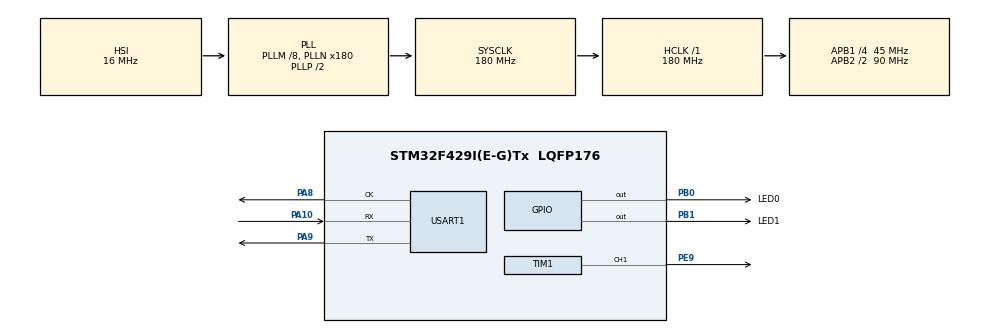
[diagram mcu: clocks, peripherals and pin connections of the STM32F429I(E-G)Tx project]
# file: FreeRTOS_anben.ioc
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FREERTOS.Tasks01=defaultTask,24,128,StartDefaultTask,Default,NULL,Dynamic,NULL,NULL
FREERTOS.configUSE_NEWLIB_REENTRANT=1
Mcu.Family=STM32F4
Mcu.Name=STM32F429I(E-G)Tx
Mcu.Package=LQFP176
NVIC.PriorityGroup=NVIC_PRIORITYGROUP_4
NVIC.TIM2_IRQn=true\:15\:0\:false\:false\:true\:false\:false\:true\:true
NVIC.TimeBase=TIM2_IRQn
NVIC.TimeBaseIP=TIM2
PA0/WKUP.Mode=SYS_WakeUp0
PA0/WKUP.Signal=SYS_WKUP
PA10.Mode=Synchronous
PA10.Signal=USART1_RX
PA13.Mode=Serial_Wire
PA13.Signal=SYS_JTMS-SWDIO
PA14.Mode=Serial_Wire
PA14.Signal=SYS_JTCK-SWCLK
PA8.Mode=Synchronous
PA8.Signal=USART1_CK
PA9.Mode=Synchronous
PA9.Signal=USART1_TX
PB0.GPIO_Label=LED0
PB0.Signal=GPIO_Output
PB1.GPIO_Label=LED1
PB1.Signal=GPIO_Output
PC14/OSC32_IN.Mode=LSE-External-Oscillator
PC14/OSC32_IN.Signal=RCC_OSC32_IN
PC15/OSC32_OUT.Mode=LSE-External-Oscillator
PC15/OSC32_OUT.Signal=RCC_OSC32_OUT
PE9.Signal=S_TIM1_CH1
PH0/OSC_IN.Mode=HSE-External-Oscillator
PH0/OSC_IN.Signal=RCC_OSC_IN
PH1/OSC_OUT.Mode=HSE-External-Oscillator
PH1/OSC_OUT.Signal=RCC_OSC_OUT
ProjectManager.HeapSize=0x200
ProjectManager.StackSize=0x400
ProjectManager.TargetToolchain=STM32CubeIDE
RCC.48MHZClocksFreq_Value=90000000
RCC.AHBFreq_Value=180000000
RCC.APB1CLKDivider=RCC_HCLK_DIV4
RCC.APB1Freq_Value=45000000
RCC.APB1TimFreq_Value=90000000
RCC.APB2CLKDivider=RCC_HCLK_DIV2
RCC.APB2Freq_Value=90000000
RCC.APB2TimFreq_Value=180000000
RCC.CortexFreq_Value=180000000
RCC.HCLKFreq_Value=180000000
RCC.HSE_VALUE=8000000
RCC.HSI_VALUE=16000000
RCC.PLLM=8
RCC.PLLN=180
RCC.SYSCLKFreq_VALUE=180000000
RCC.SYSCLKSource=RCC_SYSCLKSOURCE_PLLCLK
RCC.VCOOutputFreq_Value=360000000
SH.S_TIM1_CH1.0=TIM1_CH1,Output Compare1 CH1
TIM1.Channel-Output\ Compare1\ CH1=TIM_CHANNEL_1
USART1.VirtualMode=VM_SYNC
VP_FREERTOS_VS_CMSIS_V2.Mode=CMSIS_V2
VP_SYS_VS_tim2.Mode=TIM2
VP_TIM1_VS_ClockSourceINT.Mode=Internal
VP_TIM1_VS_ClockSourceITR.Mode=TriggerSource_ITR0
VP_TIM1_VS_ControllerModeReset.Mode=Reset Mode
board=custom

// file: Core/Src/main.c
/* USER CODE BEGIN Header */
/**
  ******************************************************************************
  * @file           : main.c
  * @brief          : Main program body
  ******************************************************************************
  * @attention
  *
  * Copyright (c) 2024 STMicroelectronics.
  * All rights reserved.
  *
  * This software is licensed under terms that can be found in the LICENSE file
  * in the root directory of this software component.
  * If no LICENSE file comes with this software, it is provided AS-IS.
  *
  ******************************************************************************
  */
/* USER CODE END Header */
#include "main.h"
#include "cmsis_os.h"
#include "tim.h"
#include "usart.h"
#include "gpio.h"
#include <stdio.h>

void SystemClock_Config(void);
void MX_FREERTOS_Init(void);

int main(void)
{

  /* MCU Configuration--------------------------------------------------------*/

  /* Reset of all peripherals, Initializes the Flash interface and the Systick. */
  HAL_Init();

  /* Configure the system clock */
  SystemClock_Config();

  /* Initialize all configured peripherals */
  MX_GPIO_Init();
  MX_TIM1_Init();
  MX_USART1_Init();

  /* Init scheduler */
  osKernelInitialize();

  /* Call init function for freertos objects (in cmsis_os2.c) */
  MX_FREERTOS_Init();

  /* Start scheduler */
  osKernelStart();

  /* We should never get here as control is now taken by the scheduler */

  /* Infinite loop */
  while (1)
  {
	  HAL_GPIO_TogglePin(LED0_GPIO_Port,LED0_Pin);
	  HAL_GPIO_TogglePin(LED1_GPIO_Port,LED1_Pin);
	  printf("this is a freertos demo!\r\n");
	  HAL_Delay(500);
  }
}

void SystemClock_Config(void)
{
  RCC_OscInitTypeDef RCC_OscInitStruct = {0};
  RCC_ClkInitTypeDef RCC_ClkInitStruct = {0};

  /** Configure the main internal regulator output voltage
  */
  __HAL_RCC_PWR_CLK_ENABLE();
  __HAL_PWR_VOLTAGESCALING_CONFIG(PWR_REGULATOR_VOLTAGE_SCALE1);

  /** Initializes the RCC Oscillators according to the specified parameters
  * in the RCC_OscInitTypeDef structure.
  */
  RCC_OscInitStruct.OscillatorType = RCC_OSCILLATORTYPE_HSI;
  RCC_OscInitStruct.HSIState = RCC_HSI_ON;
  RCC_OscInitStruct.HSICalibrationValue = RCC_HSICALIBRATION_DEFAULT;
  RCC_OscInitStruct.PLL.PLLState = RCC_PLL_ON;
  RCC_OscInitStruct.PLL.PLLSource = RCC_PLLSOURCE_HSI;
  RCC_OscInitStruct.PLL.PLLM = 8;
  RCC_OscInitStruct.PLL.PLLN = 180;
  RCC_OscInitStruct.PLL.PLLP = RCC_PLLP_DIV2;
  RCC_OscInitStruct.PLL.PLLQ = 4;
  if (HAL_RCC_OscConfig(&RCC_OscInitStruct) != HAL_OK)
  {
    Error_Handler();
  }

  /** Activate the Over-Drive mode
  */
  if (HAL_PWREx_EnableOverDrive() != HAL_OK)
  {
    Error_Handler();
  }

  /** Initializes the CPU, AHB and APB buses clocks
  */
  RCC_ClkInitStruct.ClockType = RCC_CLOCKTYPE_HCLK|RCC_CLOCKTYPE_SYSCLK
                              |RCC_CLOCKTYPE_PCLK1|RCC_CLOCKTYPE_PCLK2;
  RCC_ClkInitStruct.SYSCLKSource = RCC_SYSCLKSOURCE_PLLCLK;
  RCC_ClkInitStruct.AHBCLKDivider = RCC_SYSCLK_DIV1;
  RCC_ClkInitStruct.APB1CLKDivider = RCC_HCLK_DIV4;
  RCC_ClkInitStruct.APB2CLKDivider = RCC_HCLK_DIV2;

  if (HAL_RCC_ClockConfig(&RCC_ClkInitStruct, FLASH_LATENCY_5) != HAL_OK)
  {
    Error_Handler();
  }
}

void HAL_TIM_PeriodElapsedCallback(TIM_HandleTypeDef *htim)
{
  if (htim->Instance == TIM2) {
    HAL_IncTick();
  }
}

void Error_Handler(void)
{
  __disable_irq();
  while (1)
  {
  }
}

#ifdef __GNUC__
#define PUTCHAR_PROTOTYPE int __io_putchar(int ch)
#else
#define PUTCHAR_PROTOTYPE int fputc(int ch, FILE* f)
#endif /* __GNUC__ */

#ifdef __cplusplus
extern "C" {
#endif //__cplusplus

PUTCHAR_PROTOTYPE
{
	HAL_USART_Transmit(&husart1,(const uint8_t *)&ch,sizeof(char),HAL_MAX_DELAY-1);
  return (ch);
}

#ifdef __cplusplus
}
#endif //__cplusplus

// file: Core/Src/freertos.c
/* USER CODE BEGIN Header */
/**
  ******************************************************************************
  * File Name          : freertos.c
  * Description        : Code for freertos applications
  ******************************************************************************
  * @attention
  *
  * Copyright (c) 2024 STMicroelectronics.
  * All rights reserved.
  *
  * This software is licensed under terms that can be found in the LICENSE file
  * in the root directory of this software component.
  * If no LICENSE file comes with this software, it is provided AS-IS.
  *
  ******************************************************************************
  */
/* USER CODE END Header */

#include "FreeRTOS.h"
#include "task.h"
#include "main.h"
#include "cmsis_os.h"
#include <stdio.h>

/* Definitions for defaultTask */
osThreadId_t defaultTaskHandle;
osThreadId_t ledTaskHandle;
const osThreadAttr_t defaultTask_attributes = {
  .name = "defaultTask",
  .stack_size = 128 * 4,
  .priority = (osPriority_t) osPriorityNormal,
};

const osThreadAttr_t ledTask_attributes = {
  .name = "LedTask",
  .stack_size = 128 * 4,
  .priority = (osPriority_t) osPriorityNormal+1,
};

void StartDefaultTask(void *argument);
void LedTask(void *argument);

static void osTimerCallback (void *argument)
{
  (void) argument;

  /* Toggle LED1 */
  HAL_GPIO_TogglePin(LED1_GPIO_Port,LED1_Pin);
  printf("I'm timer!\r\n");
}

void MX_FREERTOS_Init(void); /* (MISRA C 2004 rule 8.1) */

void MX_FREERTOS_Init(void) {

  /* USER CODE BEGIN RTOS_TIMERS */
  /* start timers, add new ones, ... */
	osTimerId_t osTimer1;
	osTimer1 = osTimerNew(osTimerCallback,osTimerPeriodic, NULL,NULL);

	osTimerStart(osTimer1, 200);
  /* USER CODE END RTOS_TIMERS */

  /* Create the thread(s) */
  /* creation of defaultTask */
  defaultTaskHandle = osThreadNew(StartDefaultTask, NULL, &defaultTask_attributes);
  ledTaskHandle = osThreadNew(LedTask, NULL, &ledTask_attributes);

}

void StartDefaultTask(void *argument)
{
  for(;;)
  {
	  osDelay(1);
  }
}

void LedTask(void *argument)
{
  /* USER CODE BEGIN StartDefaultTask */
  /* Infinite loop */
  for(;;)
  {
	  HAL_GPIO_TogglePin(LED0_GPIO_Port,LED0_Pin);
	  printf("I'm task!\r\n");
	  osDelay(1000);
  }
  /* USER CODE END StartDefaultTask */
}
